# A31S13x register map
Vendor: VENDOR ABOV Semiconductor Co., Ltd.; Series: A31S13x; File version: 1.0
CPU: CM0+ r0p1, little endian, no MPU, no FPU, VTOR, 2 interrupt priority bits
Registers are 32-bit, read-write, reset 0x0 unless marked. A register's access mark holds for its fields unless they carry their own. Offsets are from the block's base; [hi:lo] are bit positions; {n}, {i} and the like mark numbered series; 'fields as' and 'values as' point back to an identical list.

## Pn — Port Control Unit & GPIO Port n
Base 0x50000000
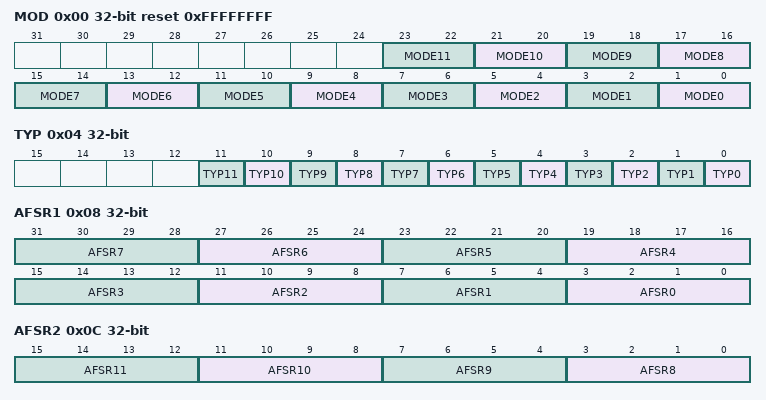
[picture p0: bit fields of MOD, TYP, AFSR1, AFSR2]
0x00 MOD reset 0xFFFFFFFF — Port n Mode Register
  [all] fields
    0=Input Mode; 1=Output Mode; 2=Alternative Function Mode
  [2n+1:2n] MODE{n} (n=0..11) — Port n Mode Selection {n}
0x04 TYP — Port n Output Type Selection Register
  [all] fields
    0=Push-Pull Output; 1=Open-Drain Output
  [n] TYP{n} (n=0..11) — Port n Output Type Selection {n}
0x08 AFSR1 — Port n Alternative Function Selection Register 1
  [all] fields
    {v}=AF{v} (Alternative Function {v} (AF{v})) (v=0..5)
  [4n+3:4n] AFSR{n} (n=0..7) — Port n Alternative Function Selection {n}
0x0C AFSR2 — Port n Alternative Function Selection Register 2
  [all] fields
    {v}=AF{v} (Alternative Function {v} (AF{v})) (v=0..5)
  [4n-29:4n-32] AFSR{n} (n=8..11) — Port n Alternative Function Selection {n}
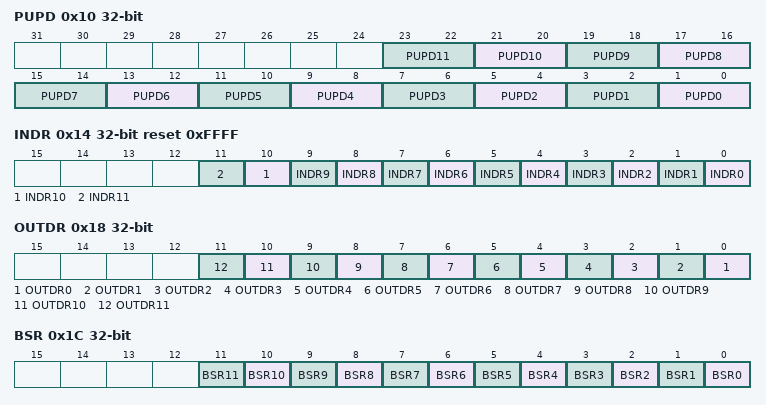
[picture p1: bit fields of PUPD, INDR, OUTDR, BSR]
0x10 PUPD — Port n Pull-Up/Down Resistor Selection Register
  [all] fields
    0=Disable pull-up/down resistor; 1=Enable pull-up resistor; 2=EnablePD (Enable pull-down resistor.)
  [2n+1:2n] PUPD{n} (n=0..11) — Port n Pull-Up/Down Resistor Selection {n}
0x14 INDR ro reset 0xFFFF — Port n Input Data Register
  [n] INDR{n} (n=0..11) — Port n Input Data {n}
0x18 OUTDR — Port n Output Data Register
  [n] OUTDR{n} (n=0..11) — Port n Output Data {n}
0x1C BSR wo — Port n Output Bit Set Register
  [all] fields
    0=NoEffect; 1=Set (Set the corresponding OUTDRx bit (Automatically cleared to 0.))
  [n] BSR{n} (n=0..11) — Port n Output Bit Set {n}
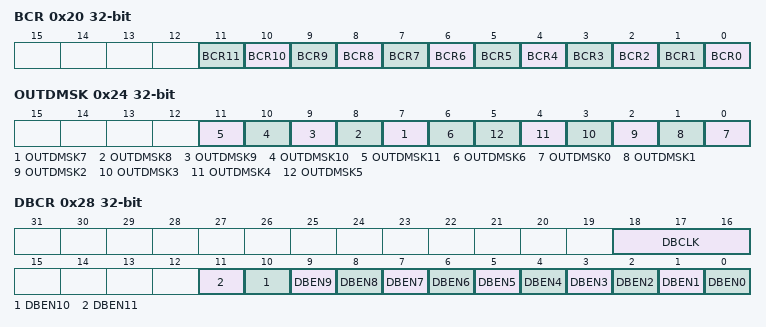
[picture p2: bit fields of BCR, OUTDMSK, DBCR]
0x20 BCR wo — Port n Output Bit Clear Register
  [all] fields
    0=NoEffect; 1=Clear the corresponding OUTDRx bit. (Automatically cleared to 0.)
  [n] BCR{n} (n=0..11) — Port n Output Bit Clear {n}
0x24 OUTDMSK — Port n Output Data Mask Register
  [n] OUTDMSK{n} (n=7..11) — Port n Output Data Mask {n}
    0=Unmask. The corresponding OUTDRx bit can be changed.; 1=Mask. The corresponding OUTDRx bit is protected.
  [6] OUTDMSK6 — Port n Output Data Mask 6
  [n] OUTDMSK{n} (n=0..5) — Port n Output Data Mask {n}
    values as OUTDMSK7
0x28 DBCR — Port n Debounce Control Register
  [18:16] DBCLK — Port n Debounce Filter Sampling Clock Selection
    0=HCLK1; 1=HCLK4; 2=HCLK16; 3=HCLK64; 4=HCLK256; 5=HCLK1024
  [n] DBEN{n} (n=0..11) — Port n Debounce Enable {n}
    0=Disable debounce filter; 1=Enable debounce filter

## PA — Port Control Unit & GPIO Port A
Base 0x30000000
Registers as Pn; these are added or differ:
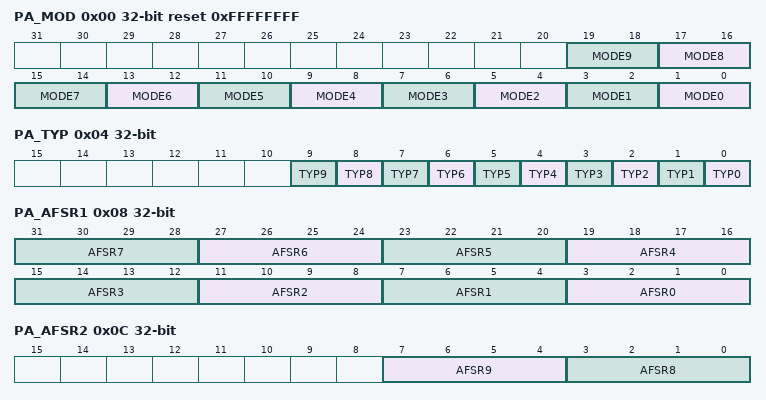
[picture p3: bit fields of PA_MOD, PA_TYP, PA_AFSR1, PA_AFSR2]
0x00 PA_MOD reset 0xFFFFFFFF (alternate view of MOD) — Port n Mode Register
  [2n+1:2n] MODE{n} (n=0..9) — Port n Mode Selection {n}
0x04 PA_TYP (alternate view of TYP) — Port n Output Type Selection Register
  [n] TYP{n} (n=0..9) — Port n Output Type Selection {n}
0x08 PA_AFSR1 (alternate view of AFSR1) — Port n Alternative Function Selection Register 1
  [4n+3:4n] AFSR{n} (n=0..7) — Port n Alternative Function Selection {n}
0x0C PA_AFSR2 (alternate view of AFSR2) — Port n Alternative Function Selection Register 2
  [7:4] AFSR9 — Port n Alternative Function Selection 9
  [3:0] AFSR8 — Port n Alternative Function Selection 8
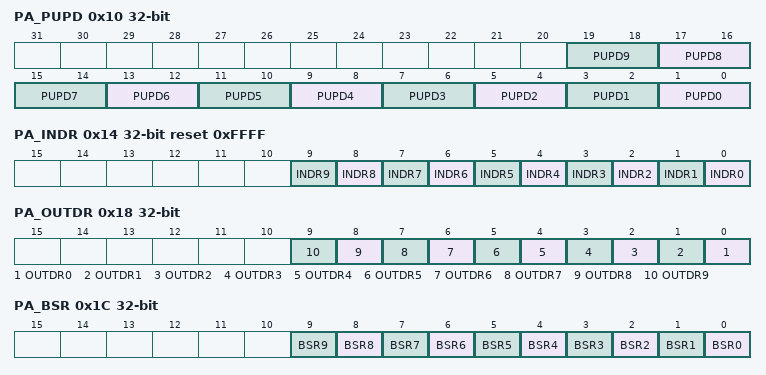
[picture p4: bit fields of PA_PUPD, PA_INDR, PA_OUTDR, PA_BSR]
0x10 PA_PUPD (alternate view of PUPD) — Port n Pull-Up/Down Resistor Selection Register
  [2n+1:2n] PUPD{n} (n=0..9) — Port n Pull-Up/Down Resistor Selection {n}
0x14 PA_INDR ro reset 0xFFFF (alternate view of INDR) — Port n Input Data Register
  [n] INDR{n} (n=0..9) — Port n Input Data {n}
0x18 PA_OUTDR (alternate view of OUTDR) — Port n Output Data Register
  [n] OUTDR{n} (n=0..9) — Port n Output Data {n}
0x1C PA_BSR wo (alternate view of BSR) — Port n Output Bit Set Register
  [n] BSR{n} (n=0..9) — Port n Output Bit Set {n}
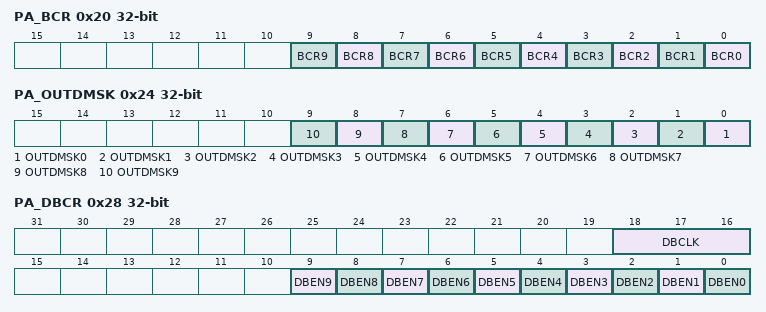
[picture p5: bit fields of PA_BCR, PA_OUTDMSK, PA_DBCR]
0x20 PA_BCR wo (alternate view of BCR) — Port n Output Bit Clear Register
  [n] BCR{n} (n=0..9) — Port n Output Bit Clear {n}
0x24 PA_OUTDMSK (alternate view of OUTDMSK) — Port n Output Data Mask Register
  [n] OUTDMSK{n} (n=0..9) — Port n Output Data Mask {n}
0x28 PA_DBCR (alternate view of DBCR) — Port n Debounce Control Register
  [18:16] DBCLK — Port n Debounce Filter Sampling Clock Selection
  [n] DBEN{n} (n=0..9) — Port n Debounce Enable {n}

## PB — Port Control Unit & GPIO Port B
Base 0x30000100
Registers as Pn; these are added or differ:
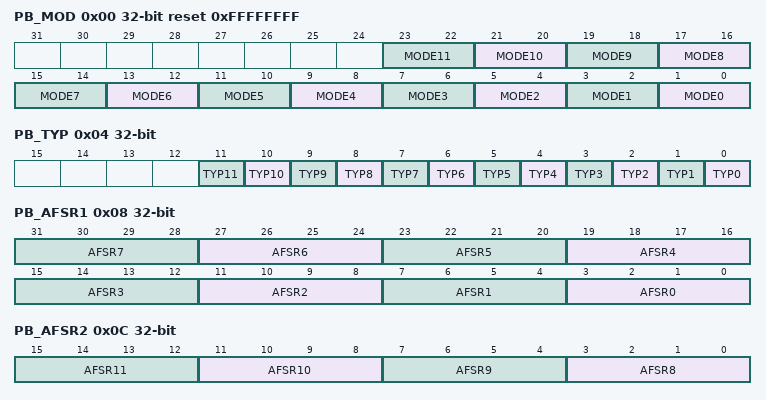
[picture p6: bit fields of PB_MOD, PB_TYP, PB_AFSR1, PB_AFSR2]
0x00 PB_MOD reset 0xFFFFFFFF (alternate view of MOD) — Port n Mode Register
  [2n+1:2n] MODE{n} (n=0..11) — Port n Mode Selection {n}
0x04 PB_TYP (alternate view of TYP) — Port n Output Type Selection Register
  [n] TYP{n} (n=0..11) — Port n Output Type Selection {n}
0x08 PB_AFSR1 (alternate view of AFSR1) — Port n Alternative Function Selection Register 1
  [4n+3:4n] AFSR{n} (n=0..7) — Port n Alternative Function Selection {n}
0x0C PB_AFSR2 (alternate view of AFSR2) — Port n Alternative Function Selection Register 2
  [4n-29:4n-32] AFSR{n} (n=8..11) — Port n Alternative Function Selection {n}
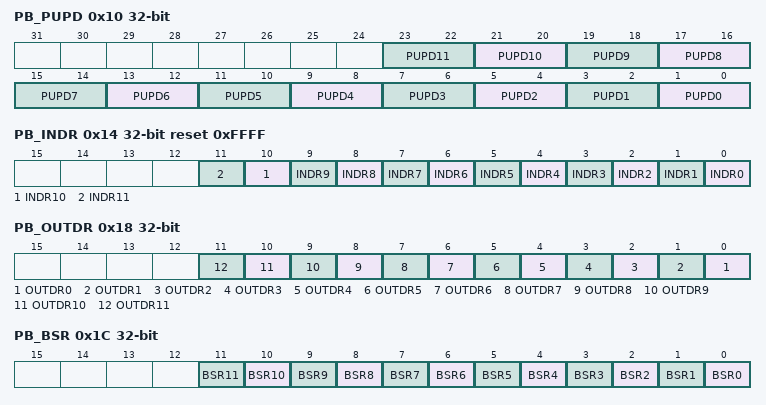
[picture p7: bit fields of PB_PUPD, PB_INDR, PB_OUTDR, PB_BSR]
0x10 PB_PUPD (alternate view of PUPD) — Port n Pull-Up/Down Resistor Selection Register
  [2n+1:2n] PUPD{n} (n=0..11) — Port n Pull-Up/Down Resistor Selection {n}
0x14 PB_INDR ro reset 0xFFFF (alternate view of INDR) — Port n Input Data Register
  [n] INDR{n} (n=0..11) — Port n Input Data {n}
0x18 PB_OUTDR (alternate view of OUTDR) — Port n Output Data Register
  [n] OUTDR{n} (n=0..11) — Port n Output Data {n}
0x1C PB_BSR wo (alternate view of BSR) — Port n Output Bit Set Register
  [n] BSR{n} (n=0..11) — Port n Output Bit Set {n}
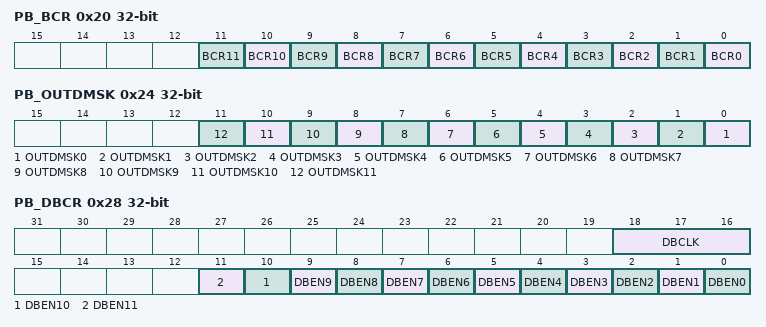
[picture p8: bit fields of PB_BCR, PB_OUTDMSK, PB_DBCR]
0x20 PB_BCR wo (alternate view of BCR) — Port n Output Bit Clear Register
  [n] BCR{n} (n=0..11) — Port n Output Bit Clear {n}
0x24 PB_OUTDMSK (alternate view of OUTDMSK) — Port n Output Data Mask Register
  [n] OUTDMSK{n} (n=0..11) — Port n Output Data Mask {n}
0x28 PB_DBCR (alternate view of DBCR) — Port n Debounce Control Register
  [18:16] DBCLK — Port n Debounce Filter Sampling Clock Selection
  [n] DBEN{n} (n=0..11) — Port n Debounce Enable {n}

## PC — Port Control Unit & GPIO Port C
Base 0x30000200
Registers as Pn; these are added or differ:
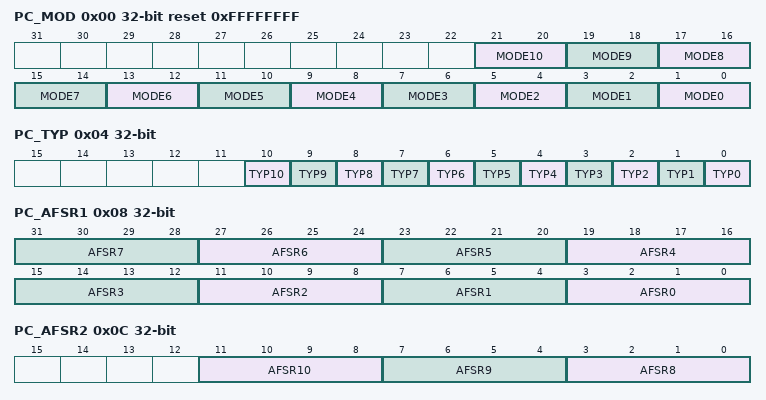
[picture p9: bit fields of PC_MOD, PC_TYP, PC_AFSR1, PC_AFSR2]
0x00 PC_MOD reset 0xFFFFFFFF (alternate view of MOD) — Port n Mode Register
  [2n+1:2n] MODE{n} (n=0..10) — Port n Mode Selection {n}
0x04 PC_TYP (alternate view of TYP) — Port n Output Type Selection Register
  [n] TYP{n} (n=0..10) — Port n Output Type Selection {n}
0x08 PC_AFSR1 (alternate view of AFSR1) — Port n Alternative Function Selection Register 1
  [4n+3:4n] AFSR{n} (n=0..7) — Port n Alternative Function Selection {n}
0x0C PC_AFSR2 (alternate view of AFSR2) — Port n Alternative Function Selection Register 2
  [11:8] AFSR10 — Port n Alternative Function Selection 10
  [7:4] AFSR9 — Port n Alternative Function Selection 9
  [3:0] AFSR8 — Port n Alternative Function Selection 8
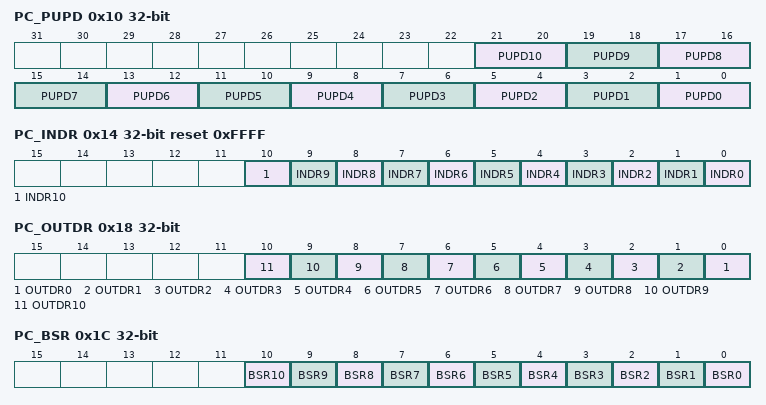
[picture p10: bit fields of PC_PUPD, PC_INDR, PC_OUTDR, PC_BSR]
0x10 PC_PUPD (alternate view of PUPD) — Port n Pull-Up/Down Resistor Selection Register
  [2n+1:2n] PUPD{n} (n=0..10) — Port n Pull-Up/Down Resistor Selection {n}
0x14 PC_INDR ro reset 0xFFFF (alternate view of INDR) — Port n Input Data Register
  [n] INDR{n} (n=0..10) — Port n Input Data {n}
0x18 PC_OUTDR (alternate view of OUTDR) — Port n Output Data Register
  [n] OUTDR{n} (n=0..10) — Port n Output Data {n}
0x1C PC_BSR wo (alternate view of BSR) — Port n Output Bit Set Register
  [n] BSR{n} (n=0..10) — Port n Output Bit Set {n}
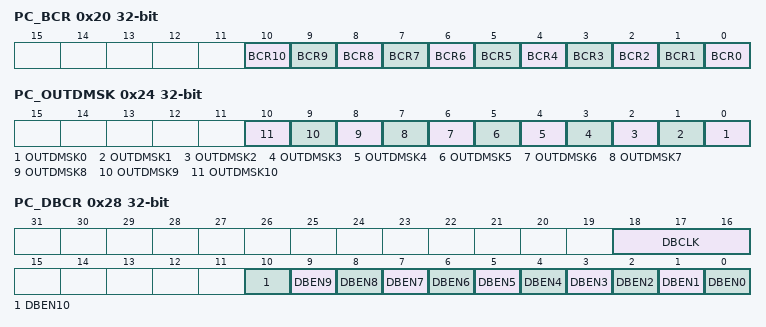
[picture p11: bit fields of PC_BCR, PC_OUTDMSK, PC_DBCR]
0x20 PC_BCR wo (alternate view of BCR) — Port n Output Bit Clear Register
  [n] BCR{n} (n=0..10) — Port n Output Bit Clear {n}
0x24 PC_OUTDMSK (alternate view of OUTDMSK) — Port n Output Data Mask Register
  [n] OUTDMSK{n} (n=0..10) — Port n Output Data Mask {n}
0x28 PC_DBCR (alternate view of DBCR) — Port n Debounce Control Register
  [18:16] DBCLK — Port n Debounce Filter Sampling Clock Selection
  [n] DBEN{n} (n=0..10) — Port n Debounce Enable {n}

## PD — Port Control Unit & GPIO Port D
Base 0x30000300
Registers as Pn; these are added or differ:
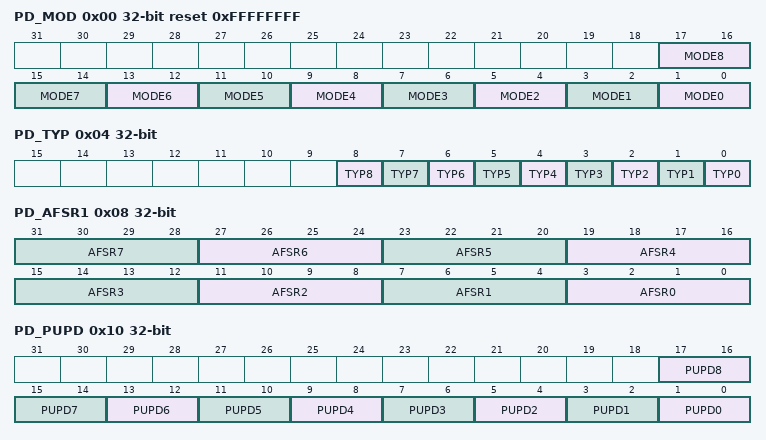
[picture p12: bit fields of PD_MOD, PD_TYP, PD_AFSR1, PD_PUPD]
0x00 PD_MOD reset 0xFFFFFFFF (alternate view of MOD) — Port n Mode Register
  [2n+1:2n] MODE{n} (n=0..8) — Port n Mode Selection {n}
0x04 PD_TYP (alternate view of TYP) — Port n Output Type Selection Register
  [n] TYP{n} (n=0..8) — Port n Output Type Selection {n}
0x08 PD_AFSR1 (alternate view of AFSR1) — Port n Alternative Function Selection Register 1
  [4n+3:4n] AFSR{n} (n=0..7) — Port n Alternative Function Selection {n}
0x0C PD_AFSR2 (alternate view of AFSR2) — Port n Alternative Function Selection Register 2
  [3:0] AFSR8 — Port n Alternative Function Selection 8
0x10 PD_PUPD (alternate view of PUPD) — Port n Pull-Up/Down Resistor Selection Register
  [2n+1:2n] PUPD{n} (n=0..8) — Port n Pull-Up/Down Resistor Selection {n}
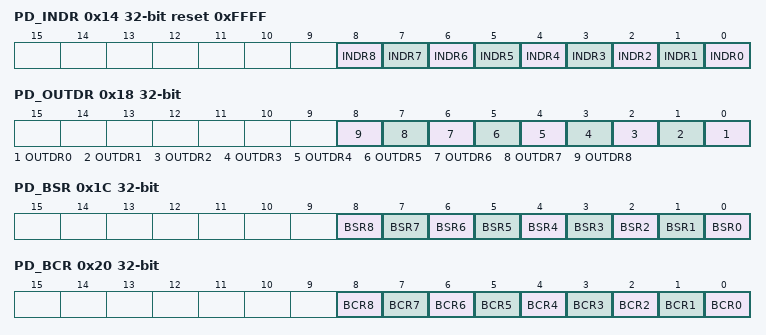
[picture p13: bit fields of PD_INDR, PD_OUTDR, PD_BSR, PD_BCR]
0x14 PD_INDR ro reset 0xFFFF (alternate view of INDR) — Port n Input Data Register
  [n] INDR{n} (n=0..8) — Port n Input Data {n}
0x18 PD_OUTDR (alternate view of OUTDR) — Port n Output Data Register
  [n] OUTDR{n} (n=0..8) — Port n Output Data {n}
0x1C PD_BSR wo (alternate view of BSR) — Port n Output Bit Set Register
  [n] BSR{n} (n=0..8) — Port n Output Bit Set {n}
0x20 PD_BCR wo (alternate view of BCR) — Port n Output Bit Clear Register
  [n] BCR{n} (n=0..8) — Port n Output Bit Clear {n}
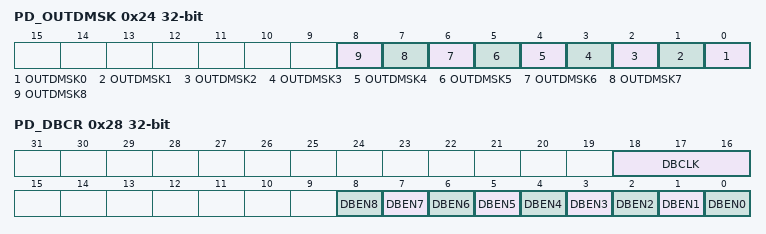
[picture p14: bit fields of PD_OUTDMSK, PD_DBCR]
0x24 PD_OUTDMSK (alternate view of OUTDMSK) — Port n Output Data Mask Register
  [n] OUTDMSK{n} (n=0..8) — Port n Output Data Mask {n}
0x28 PD_DBCR (alternate view of DBCR) — Port n Debounce Control Register
  [18:16] DBCLK — Port n Debounce Filter Sampling Clock Selection
  [n] DBEN{n} (n=0..8) — Port n Debounce Enable {n}

## PE — Port Control Unit & GPIO Port E
Base 0x30000400
Registers as Pn; these are added or differ:
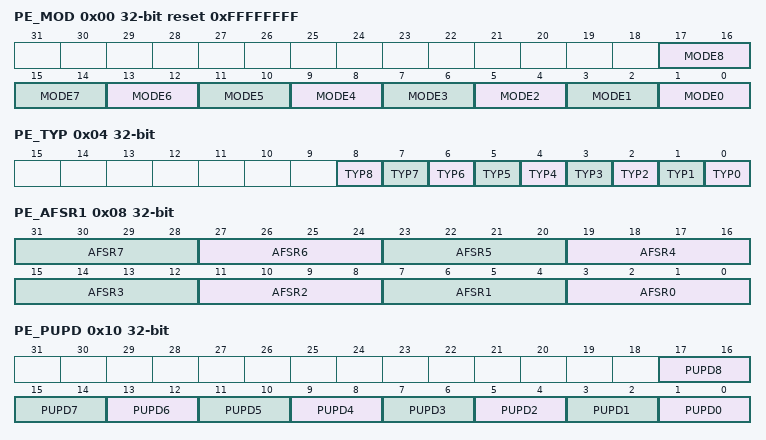
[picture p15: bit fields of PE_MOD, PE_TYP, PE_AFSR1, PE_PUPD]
0x00 PE_MOD reset 0xFFFFFFFF (alternate view of MOD) — Port n Mode Register
  [2n+1:2n] MODE{n} (n=0..8) — Port n Mode Selection {n}
0x04 PE_TYP (alternate view of TYP) — Port n Output Type Selection Register
  [n] TYP{n} (n=0..8) — Port n Output Type Selection {n}
0x08 PE_AFSR1 (alternate view of AFSR1) — Port n Alternative Function Selection Register 1
  [4n+3:4n] AFSR{n} (n=0..7) — Port n Alternative Function Selection {n}
0x0C PE_AFSR2 (alternate view of AFSR2) — Port n Alternative Function Selection Register 2
  [3:0] AFSR8 — Port n Alternative Function Selection 8
0x10 PE_PUPD (alternate view of PUPD) — Port n Pull-Up/Down Resistor Selection Register
  [2n+1:2n] PUPD{n} (n=0..8) — Port n Pull-Up/Down Resistor Selection {n}
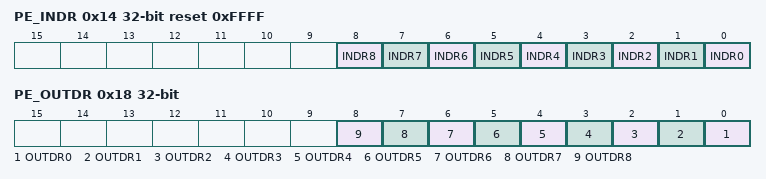
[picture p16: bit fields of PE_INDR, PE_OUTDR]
0x14 PE_INDR ro reset 0xFFFF (alternate view of INDR) — Port n Input Data Register
  [n] INDR{n} (n=0..8) — Port n Input Data {n}
0x18 PE_OUTDR (alternate view of OUTDR) — Port n Output Data Register
  [n] OUTDR{n} (n=0..8) — Port n Output Data {n}
0x1C PE_BSR wo (alternate view of BSR) — Port n Output Bit Set Register
  [n] BSR{n} (n=0..8) — Port n Output Bit Set {n}
0x20 PE_BCR wo (alternate view of BCR) — Port n Output Bit Clear Register
  [n] BCR{n} (n=0..8) — Port n Output Bit Clear {n}
0x24 PE_OUTDMSK (alternate view of OUTDMSK) — Port n Output Data Mask Register
  [n] OUTDMSK{n} (n=0..8) — Port n Output Data Mask {n}
0x28 PE_DBCR (alternate view of DBCR) — Port n Debounce Control Register
  [18:16] DBCLK — Port n Debounce Filter Sampling Clock Selection
  [n] DBEN{n} (n=0..8) — Port n Debounce Enable {n}

## PF — Port Control Unit & GPIO Port F
Base 0x30000500
Registers as Pn; these are added or differ:
0x00 PF_MOD reset 0xFFFFFFFF (alternate view of MOD) — Port n Mode Register
  [2n+1:2n] MODE{n} (n=0..9) — Port n Mode Selection {n}
0x04 PF_TYP (alternate view of TYP) — Port n Output Type Selection Register
  [n] TYP{n} (n=0..9) — Port n Output Type Selection {n}
0x08 PF_AFSR1 (alternate view of AFSR1) — Port n Alternative Function Selection Register 1
  [4n+3:4n] AFSR{n} (n=0..7) — Port n Alternative Function Selection {n}
0x0C PF_AFSR2 (alternate view of AFSR2) — Port n Alternative Function Selection Register 2
  [7:4] AFSR9 — Port n Alternative Function Selection 9
  [3:0] AFSR8 — Port n Alternative Function Selection 8
0x10 PF_PUPD (alternate view of PUPD) — Port n Pull-Up/Down Resistor Selection Register
  [2n+1:2n] PUPD{n} (n=0..9) — Port n Pull-Up/Down Resistor Selection {n}
0x14 PF_INDR ro reset 0xFFFF (alternate view of INDR) — Port n Input Data Register
  [n] INDR{n} (n=0..9) — Port n Input Data {n}
0x18 PF_OUTDR (alternate view of OUTDR) — Port n Output Data Register
  [n] OUTDR{n} (n=0..9) — Port n Output Data {n}
0x1C PF_BSR wo (alternate view of BSR) — Port n Output Bit Set Register
  [n] BSR{n} (n=0..9) — Port n Output Bit Set {n}
0x20 PF_BCR wo (alternate view of BCR) — Port n Output Bit Clear Register
  [n] BCR{n} (n=0..9) — Port n Output Bit Clear {n}
0x24 PF_OUTDMSK (alternate view of OUTDMSK) — Port n Output Data Mask Register
  [n] OUTDMSK{n} (n=0..9) — Port n Output Data Mask {n}
0x28 PF_DBCR (alternate view of DBCR) — Port n Debounce Control Register
  [18:16] DBCLK — Port n Debounce Filter Sampling Clock Selection
  [n] DBEN{n} (n=0..9) — Port n Debounce Enable {n}
